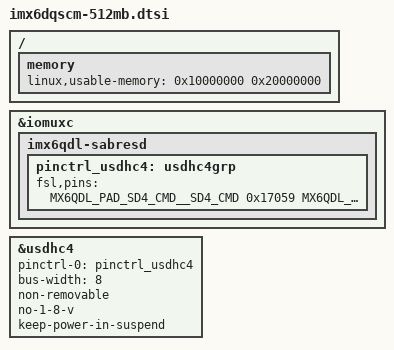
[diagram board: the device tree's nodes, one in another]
/*
 * Copyright (C) 2016 Freescale Semiconductor, Inc.
 *
 * This program is free software; you can redistribute it and/or modify
 * it under the terms of the GNU General Public License version 2 as
 * published by the Free Software Foundation.
 */

/ {
	memory: memory {
		linux,usable-memory = <0x10000000 0x20000000>;
	};
};

&iomuxc {
	imx6qdl-sabresd {

		pinctrl_usdhc4: usdhc4grp {
			fsl,pins = <
				MX6QDL_PAD_SD4_CMD__SD4_CMD		0x17059
				MX6QDL_PAD_SD4_CLK__SD4_CLK		0x10059
				MX6QDL_PAD_SD4_DAT0__SD4_DATA0		0x17059
				MX6QDL_PAD_SD4_DAT1__SD4_DATA1		0x17059
				MX6QDL_PAD_SD4_DAT2__SD4_DATA2		0x17059
				MX6QDL_PAD_SD4_DAT3__SD4_DATA3		0x17059
				MX6QDL_PAD_SD4_DAT4__SD4_DATA4		0x17059
				MX6QDL_PAD_SD4_DAT5__SD4_DATA5		0x17059
				MX6QDL_PAD_SD4_DAT6__SD4_DATA6		0x17059
				MX6QDL_PAD_SD4_DAT7__SD4_DATA7		0x17059
			>;
		};

	};
};


&usdhc4 {
	pinctrl-names = "default";
	pinctrl-0 = <&pinctrl_usdhc4>;
	bus-width = <8>;
	non-removable;
	no-1-8-v;
	keep-power-in-suspend;
	status = "okay";
};
